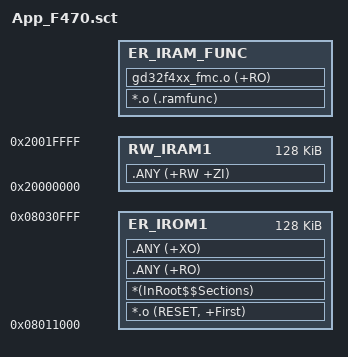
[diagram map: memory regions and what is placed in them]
; App scatter file for GD32F470VET6 (contest APP region)
; APP : 0x08011000 - 0x08030FFF (128KB)

LR_IROM1 0x08011000 0x00020000  {
  ER_IROM1 0x08011000 0x00020000  {
   *.o (RESET, +First)
   *(InRoot$$Sections)
   .ANY (+RO)
   .ANY (+XO)
  }
  RW_IRAM1 0x20000000 0x00020000  {
   .ANY (+RW +ZI)
  }
  ER_IRAM_FUNC +0  {
   *.o (.ramfunc)
   gd32f4xx_fmc.o (+RO)
  }
}
